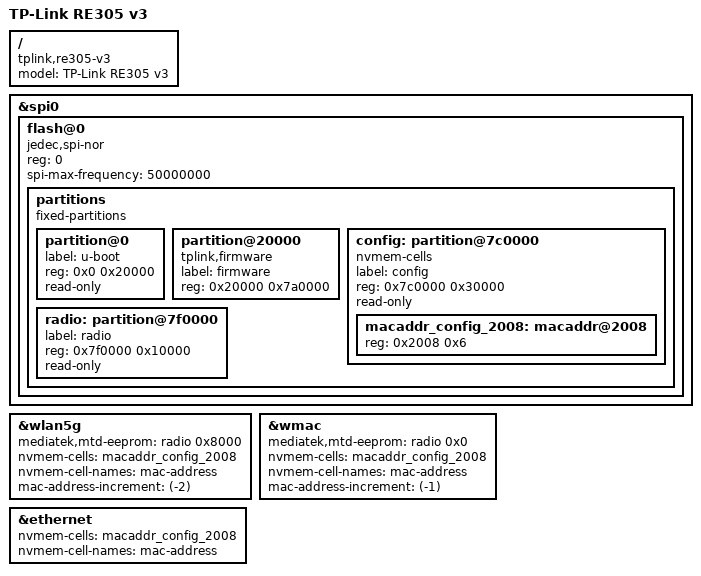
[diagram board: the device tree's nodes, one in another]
// SPDX-License-Identifier: GPL-2.0-or-later OR MIT

#include "mt7628an_tplink_re305.dtsi"

/ {
	compatible = "tplink,re305-v3", "mediatek,mt7628an-soc";
	model = "TP-Link RE305 v3";
};

&spi0 {
	status = "okay";

	flash@0 {
		compatible = "jedec,spi-nor";
		reg = <0>;
		spi-max-frequency = <50000000>;

		partitions {
			compatible = "fixed-partitions";
			#address-cells = <1>;
			#size-cells = <1>;

			partition@0 {
				label = "u-boot";
				reg = <0x0 0x20000>;
				read-only;
			};

			partition@20000 {
				compatible = "tplink,firmware";
				label = "firmware";
				reg = <0x20000 0x7a0000>;
			};

			config: partition@7c0000 {
				label = "config";
				reg = <0x7c0000 0x30000>;
				read-only;
			};

			radio: partition@7f0000 {
				label = "radio";
				reg = <0x7f0000 0x10000>;
				read-only;
			};
		};
	};
};

&wlan5g {
	mediatek,mtd-eeprom = <&radio 0x8000>;

	nvmem-cells = <&macaddr_config_2008>;
	nvmem-cell-names = "mac-address";
	mac-address-increment = <(-2)>;
};

&wmac {
	mediatek,mtd-eeprom = <&radio 0x0>;

	nvmem-cells = <&macaddr_config_2008>;
	nvmem-cell-names = "mac-address";
	mac-address-increment = <(-1)>;
};

&ethernet {
	nvmem-cells = <&macaddr_config_2008>;
	nvmem-cell-names = "mac-address";
};

&config {
	compatible = "nvmem-cells";
	#address-cells = <1>;
	#size-cells = <1>;

	macaddr_config_2008: macaddr@2008 {
		reg = <0x2008 0x6>;
	};
};
